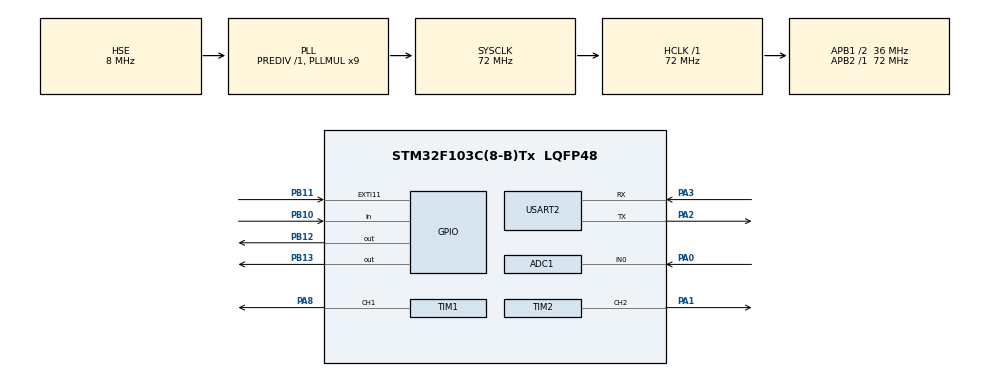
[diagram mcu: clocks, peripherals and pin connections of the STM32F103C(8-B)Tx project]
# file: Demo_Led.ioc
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ADC1.Channel-2\#ChannelRegularConversion=ADC_CHANNEL_0
ADC1.ContinuousConvMode=ENABLE
ADC1.ExternalTrigConv=ADC_SOFTWARE_START
ADC1.NbrOfConversionFlag=1
ADC1.Rank-2\#ChannelRegularConversion=1
ADC1.SamplingTime-2\#ChannelRegularConversion=ADC_SAMPLETIME_239CYCLES_5
ADC1.master=1
Dma.ADC1.1.Direction=DMA_PERIPH_TO_MEMORY
Dma.ADC1.1.Instance=DMA1_Channel1
Dma.ADC1.1.MemDataAlignment=DMA_MDATAALIGN_HALFWORD
Dma.ADC1.1.MemInc=DMA_MINC_ENABLE
Dma.ADC1.1.Mode=DMA_NORMAL
Dma.ADC1.1.PeriphDataAlignment=DMA_PDATAALIGN_HALFWORD
Dma.ADC1.1.PeriphInc=DMA_PINC_DISABLE
Dma.ADC1.1.Priority=DMA_PRIORITY_HIGH
Dma.Request0=USART2_TX
Dma.Request1=ADC1
Dma.USART2_TX.0.Direction=DMA_MEMORY_TO_PERIPH
Dma.USART2_TX.0.Instance=DMA1_Channel7
Dma.USART2_TX.0.MemDataAlignment=DMA_MDATAALIGN_BYTE
Dma.USART2_TX.0.MemInc=DMA_MINC_ENABLE
Dma.USART2_TX.0.Mode=DMA_NORMAL
Dma.USART2_TX.0.PeriphDataAlignment=DMA_PDATAALIGN_BYTE
Dma.USART2_TX.0.PeriphInc=DMA_PINC_DISABLE
Dma.USART2_TX.0.Priority=DMA_PRIORITY_HIGH
Mcu.Family=STM32F1
Mcu.Name=STM32F103C(8-B)Tx
Mcu.Package=LQFP48
NVIC.ADC1_2_IRQn=true\:0\:0\:false\:false\:true\:true\:true\:true
NVIC.DMA1_Channel1_IRQn=true\:0\:0\:false\:false\:true\:false\:true\:true
NVIC.DMA1_Channel7_IRQn=true\:0\:0\:false\:false\:true\:false\:true\:true
NVIC.EXTI15_10_IRQn=true\:0\:0\:false\:false\:true\:true\:true\:true
NVIC.PriorityGroup=NVIC_PRIORITYGROUP_4
NVIC.TIM1_UP_IRQn=true\:0\:0\:false\:false\:true\:true\:true\:true
NVIC.TIM2_IRQn=true\:0\:0\:false\:false\:true\:true\:true\:true
NVIC.USART2_IRQn=true\:0\:0\:false\:false\:true\:true\:true\:true
PA0-WKUP.Signal=ADCx_IN0
PA1.Signal=S_TIM2_CH2
PA13.Mode=Serial_Wire
PA13.Signal=SYS_JTMS-SWDIO
PA14.Mode=Serial_Wire
PA14.Signal=SYS_JTCK-SWCLK
PA2.Mode=Asynchronous
PA2.Signal=USART2_TX
PA3.Mode=Asynchronous
PA3.Signal=USART2_RX
PA8.Signal=S_TIM1_CH1
PB10.GPIO_Mode=GPIO_MODE_INPUT
PB10.GPIO_PuPd=GPIO_PULLUP
PB10.Signal=GPIO_Input
PB11.GPIO_PuPd=GPIO_PULLUP
PB11.Signal=GPXTI11
PB12.GPIO_ModeDefaultOutputPP=GPIO_MODE_OUTPUT_PP
PB12.GPIO_PuPd=GPIO_NOPULL
PB12.Signal=GPIO_Output
PB13.Signal=GPIO_Output
PD0-OSC_IN.Mode=HSE-External-Oscillator
PD0-OSC_IN.Signal=RCC_OSC_IN
PD1-OSC_OUT.Mode=HSE-External-Oscillator
PD1-OSC_OUT.Signal=RCC_OSC_OUT
ProjectManager.HeapSize=0x200
ProjectManager.StackSize=0x400
ProjectManager.TargetToolchain=MDK-ARM V5.32
RCC.ADCPresc=RCC_ADCPCLK2_DIV6
RCC.AHBFreq_Value=72000000
RCC.APB1CLKDivider=RCC_HCLK_DIV2
RCC.APB1Freq_Value=36000000
RCC.APB1TimFreq_Value=72000000
RCC.APB2Freq_Value=72000000
RCC.APB2TimFreq_Value=72000000
RCC.HCLKFreq_Value=72000000
RCC.PLLMUL=RCC_PLL_MUL9
RCC.PLLSourceVirtual=RCC_PLLSOURCE_HSE
RCC.SYSCLKFreq_VALUE=72000000
RCC.SYSCLKSource=RCC_SYSCLKSOURCE_PLLCLK
RCC.USBFreq_Value=72000000
SH.ADCx_IN0.0=ADC1_IN0,IN0
SH.S_TIM1_CH1.0=TIM1_CH1,PWM Generation1 CH1
SH.S_TIM2_CH2.0=TIM2_CH2,PWM Generation2 CH2
TIM1.AutoReloadPreload=TIM_AUTORELOAD_PRELOAD_ENABLE
TIM1.Channel-PWM\ Generation1\ CH1=TIM_CHANNEL_1
TIM1.Period=1000-1
TIM1.Prescaler=7200-1
TIM2.AutoReloadPreload=TIM_AUTORELOAD_PRELOAD_ENABLE
TIM2.Channel-PWM\ Generation2\ CH2=TIM_CHANNEL_2
TIM2.Period=1000-1
TIM2.Prescaler=72-1
USART2.VirtualMode=VM_ASYNC
VP_TIM1_VS_ClockSourceINT.Mode=Internal
VP_TIM2_VS_ClockSourceINT.Mode=Internal
board=custom

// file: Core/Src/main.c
/* USER CODE BEGIN Header */
/**
  ******************************************************************************
  * @file           : main.c
  * @brief          : Main program body
  ******************************************************************************
  * @attention
  *
  * Copyright (c) 2025 STMicroelectronics.
  * All rights reserved.
  *
  * This software is licensed under terms that can be found in the LICENSE file
  * in the root directory of this software component.
  * If no LICENSE file comes with this software, it is provided AS-IS.
  *
  ******************************************************************************
  */
/* USER CODE END Header */
#include "main.h"
#include "adc.h"
#include "dma.h"
#include "tim.h"
#include "usart.h"
#include "gpio.h"

/* USER CODE BEGIN Includes */
#include "sw2adc.h"
#include "dwt.h"
/* USER CODE END Includes */

void SystemClock_Config(void);

int main(void)
{

  /* MCU Configuration--------------------------------------------------------*/

  /* Reset of all peripherals, Initializes the Flash interface and the Systick. */
  HAL_Init();

  /* Configure the system clock */
  SystemClock_Config();

  /* Initialize all configured peripherals */
  MX_GPIO_Init();
  MX_DMA_Init();
  MX_ADC1_Init();
  MX_USART2_UART_Init();
  MX_TIM1_Init();
  MX_TIM2_Init();
  /* USER CODE BEGIN 2 */
  DWT_Init(72); // CPU 72MHz
  HAL_TIM_Base_Start_IT(&htim1);
  HAL_TIM_Base_Start_IT(&htim2);
  HAL_TIM_PWM_Start(&htim2, TIM_CHANNEL_2);
  HAL_TIM_PWM_Start(&htim1, TIM_CHANNEL_1);
  HAL_ADC_Start_DMA(&hadc1, (uint32_t*)&SW2ADC_Value, 1);
  // if(HAL_ADC_Start_IT(&hadc1) != HAL_OK)
  // {
  //   HAL_GPIO_WritePin(GPIOA, GPIO_PIN_0, GPIO_PIN_RESET);  // ??????LED0??
  // };
  HAL_UART_Transmit_DMA(&huart2, (uint8_t *)"SW2 ADC TEST\r\n", 14);
	 //HAL_GPIO_WritePin(GPIOB, GPIO_PIN_12, GPIO_PIN_SET);  // ??????LED1??
	// HAL_GPIO_WritePin(GPIOB, GPIO_PIN_12, GPIO_PIN_RESET);// ??????LED1??
//	HAL_GPIO_TogglePin(GPIOB, GPIO_PIN_12);  // ??????
//	HAL_Delay(500);
//	HAL_GPIO_TogglePin(GPIOB, GPIO_PIN_12);  // ??????
  /* USER CODE END 2 */

  /* Infinite loop */
  while (1)
  {

    /* USER CODE BEGIN 3 */
	// HAL_GPIO_TogglePin(GPIOB, GPIO_PIN_12);  // ??????
	// HAL_Delay(500);
  // printValue(SW2ADC_Value, &huart2);

	  // HAL_Delay(200);

  }
  /* USER CODE END 3 */
}

void SystemClock_Config(void)
{
  RCC_OscInitTypeDef RCC_OscInitStruct = {0};
  RCC_ClkInitTypeDef RCC_ClkInitStruct = {0};
  RCC_PeriphCLKInitTypeDef PeriphClkInit = {0};

  /** Initializes the RCC Oscillators according to the specified parameters
  * in the RCC_OscInitTypeDef structure.
  */
  RCC_OscInitStruct.OscillatorType = RCC_OSCILLATORTYPE_HSE;
  RCC_OscInitStruct.HSEState = RCC_HSE_ON;
  RCC_OscInitStruct.HSEPredivValue = RCC_HSE_PREDIV_DIV1;
  RCC_OscInitStruct.HSIState = RCC_HSI_ON;
  RCC_OscInitStruct.PLL.PLLState = RCC_PLL_ON;
  RCC_OscInitStruct.PLL.PLLSource = RCC_PLLSOURCE_HSE;
  RCC_OscInitStruct.PLL.PLLMUL = RCC_PLL_MUL9;
  if (HAL_RCC_OscConfig(&RCC_OscInitStruct) != HAL_OK)
  {
    Error_Handler();
  }

  /** Initializes the CPU, AHB and APB buses clocks
  */
  RCC_ClkInitStruct.ClockType = RCC_CLOCKTYPE_HCLK|RCC_CLOCKTYPE_SYSCLK
                              |RCC_CLOCKTYPE_PCLK1|RCC_CLOCKTYPE_PCLK2;
  RCC_ClkInitStruct.SYSCLKSource = RCC_SYSCLKSOURCE_PLLCLK;
  RCC_ClkInitStruct.AHBCLKDivider = RCC_SYSCLK_DIV1;
  RCC_ClkInitStruct.APB1CLKDivider = RCC_HCLK_DIV2;
  RCC_ClkInitStruct.APB2CLKDivider = RCC_HCLK_DIV1;

  if (HAL_RCC_ClockConfig(&RCC_ClkInitStruct, FLASH_LATENCY_2) != HAL_OK)
  {
    Error_Handler();
  }
  PeriphClkInit.PeriphClockSelection = RCC_PERIPHCLK_ADC;
  PeriphClkInit.AdcClockSelection = RCC_ADCPCLK2_DIV6;
  if (HAL_RCCEx_PeriphCLKConfig(&PeriphClkInit) != HAL_OK)
  {
    Error_Handler();
  }
}

void Error_Handler(void)
{
  __disable_irq();
  while (1)
  {
  }
}
